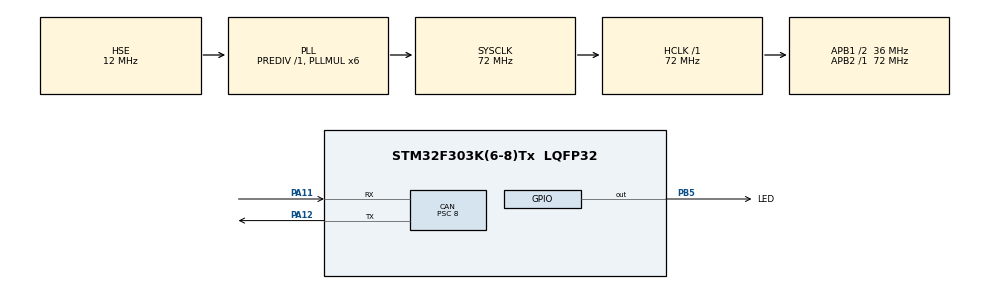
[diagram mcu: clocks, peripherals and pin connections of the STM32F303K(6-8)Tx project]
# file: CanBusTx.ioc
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CAN.BS1=CAN_BS1_7TQ
CAN.CalculateBaudRate=500000
CAN.CalculateTimeBit=1999.99
CAN.CalculateTimeQuantum=222.22222222222223
CAN.Prescaler=8
Mcu.Family=STM32F3
Mcu.Name=STM32F303K(6-8)Tx
Mcu.Package=LQFP32
NVIC.CAN_RX0_IRQn=true\:0\:0\:false\:false\:true\:true\:true
NVIC.CAN_RX1_IRQn=true\:0\:0\:false\:false\:true\:true\:true
NVIC.PriorityGroup=NVIC_PRIORITYGROUP_4
PA11.Mode=CAN_Activate
PA11.Signal=CAN_RX
PA12.Mode=CAN_Activate
PA12.Signal=CAN_TX
PA13.Mode=Serial_Wire
PA13.Signal=SYS_JTMS-SWDIO
PA14.Mode=Serial_Wire
PA14.Signal=SYS_JTCK-SWCLK
PB5.GPIO_Label=LED
PB5.Signal=GPIO_Output
PF0\ /\ OSC_IN.Mode=HSE-External-Oscillator
PF0\ /\ OSC_IN.Signal=RCC_OSC_IN
PF1\ /\ OSC_OUT.Mode=HSE-External-Oscillator
PF1\ /\ OSC_OUT.Signal=RCC_OSC_OUT
ProjectManager.HeapSize=0x200
ProjectManager.StackSize=0x400
ProjectManager.TargetToolchain=STM32CubeIDE
RCC.AHBFreq_Value=72000000
RCC.APB1CLKDivider=RCC_HCLK_DIV2
RCC.APB1Freq_Value=36000000
RCC.APB1TimFreq_Value=72000000
RCC.APB2Freq_Value=72000000
RCC.APB2TimFreq_Value=72000000
RCC.CortexFreq_Value=72000000
RCC.HCLKFreq_Value=72000000
RCC.HSE_VALUE=12000000
RCC.HSI_VALUE=8000000
RCC.PLLMUL=RCC_PLL_MUL6
RCC.PLLSourceVirtual=RCC_PLLSOURCE_HSE
RCC.SYSCLKFreq_VALUE=72000000
RCC.SYSCLKSourceVirtual=RCC_SYSCLKSOURCE_PLLCLK
board=custom

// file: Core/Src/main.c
/* USER CODE BEGIN Header */
/**
  ******************************************************************************
  * @file           : main.c
  * @brief          : Main program body
  ******************************************************************************
  * @attention
  *
  * <h2><center>&copy; Copyright (c) 2021 STMicroelectronics.
  * All rights reserved.</center></h2>
  *
  * This software component is licensed by ST under BSD 3-Clause license,
  * the "License"; You may not use this file except in compliance with the
  * License. You may obtain a copy of the License at:
  *                        opensource.org/licenses/BSD-3-Clause
  *
  ******************************************************************************
  */
/* USER CODE END Header */
#include "main.h"
#include "can.h"
#include "gpio.h"
#include <stdlib.h>

/* USER CODE BEGIN PV */
CAN_FilterTypeDef sFilterConfig;
CAN_TxHeaderTypeDef TxHeader;
CAN_RxHeaderTypeDef RxHeader;
/* USER CODE END PV */

void SystemClock_Config(void);
/* USER CODE BEGIN PFP */
void CAN1_Tx(uint8_t stdid, uint16_t TxMessage[8]);
/* USER CODE END PFP */

int main(void)
{

  /* MCU Configuration--------------------------------------------------------*/

  /* Reset of all peripherals, Initializes the Flash interface and the Systick. */
  HAL_Init();

  /* Configure the system clock */
  SystemClock_Config();

  /* Initialize all configured peripherals */
  MX_GPIO_Init();
  MX_CAN_Init();
  /* USER CODE BEGIN 2 */
  HAL_CAN_Start(&hcan);

  sFilterConfig.FilterMode = CAN_FILTERMODE_IDMASK;
  sFilterConfig.FilterScale = CAN_FILTERSCALE_32BIT;
  sFilterConfig.FilterIdHigh = 0x0000;
  sFilterConfig.FilterIdLow = 0x0000;
  sFilterConfig.FilterMaskIdHigh = 0x0000;
  sFilterConfig.FilterMaskIdLow= 0x0000;
  sFilterConfig.FilterFIFOAssignment = CAN_FILTER_FIFO0;
  sFilterConfig.FilterActivation = ENABLE;
  sFilterConfig.FilterBank = 0;

  HAL_CAN_ConfigFilter(&hcan, &sFilterConfig);
  uint8_t s=1;

  /* USER CODE END 2 */

  /* Infinite loop */
  while (1)
  {

    /* USER CODE BEGIN 3 */
	  HAL_GPIO_WritePin(LED_GPIO_Port, LED_Pin, GPIO_PIN_SET);
	  uint16_t rawdata[4];
	  uint16_t rawdata2[4];

	  rawdata[0] += s*100;
	  if (rawdata[0]<0 || rawdata[0]>8000) s*=-1;
	  rawdata[1] = rand()%6+1;				//marcia
	  rawdata[2] = rand()%3+1;				//mappa
	  rawdata[3] = rand()%2;				//drs
	  rawdata2[0] = rand()%60+50;			//oil temp
	  rawdata2[1] = rand()%20+30;			//air temp
	  rawdata2[2] = rand()%60+50;			//h2o temp
	  rawdata2[3] = rand()%4+10;			//battery voltage

	  CAN1_Tx(17,rawdata);
	  CAN1_Tx(18,rawdata2);
	  HAL_Delay(100);

  }
  /* USER CODE END 3 */
}

void SystemClock_Config(void)
{
  RCC_OscInitTypeDef RCC_OscInitStruct = {0};
  RCC_ClkInitTypeDef RCC_ClkInitStruct = {0};

  /** Initializes the RCC Oscillators according to the specified parameters
  * in the RCC_OscInitTypeDef structure.
  */
  RCC_OscInitStruct.OscillatorType = RCC_OSCILLATORTYPE_HSE;
  RCC_OscInitStruct.HSEState = RCC_HSE_ON;
  RCC_OscInitStruct.HSEPredivValue = RCC_HSE_PREDIV_DIV1;
  RCC_OscInitStruct.HSIState = RCC_HSI_ON;
  RCC_OscInitStruct.PLL.PLLState = RCC_PLL_ON;
  RCC_OscInitStruct.PLL.PLLSource = RCC_PLLSOURCE_HSE;
  RCC_OscInitStruct.PLL.PLLMUL = RCC_PLL_MUL6;
  if (HAL_RCC_OscConfig(&RCC_OscInitStruct) != HAL_OK)
  {
    Error_Handler();
  }
  /** Initializes the CPU, AHB and APB buses clocks
  */
  RCC_ClkInitStruct.ClockType = RCC_CLOCKTYPE_HCLK|RCC_CLOCKTYPE_SYSCLK
                              |RCC_CLOCKTYPE_PCLK1|RCC_CLOCKTYPE_PCLK2;
  RCC_ClkInitStruct.SYSCLKSource = RCC_SYSCLKSOURCE_PLLCLK;
  RCC_ClkInitStruct.AHBCLKDivider = RCC_SYSCLK_DIV1;
  RCC_ClkInitStruct.APB1CLKDivider = RCC_HCLK_DIV2;
  RCC_ClkInitStruct.APB2CLKDivider = RCC_HCLK_DIV1;

  if (HAL_RCC_ClockConfig(&RCC_ClkInitStruct, FLASH_LATENCY_2) != HAL_OK)
  {
    Error_Handler();

  }
}

/* USER CODE BEGIN 4 */

void CAN1_Tx(uint8_t stdid, uint16_t message[8]){

	CAN_TxHeaderTypeDef TxHeader;

	uint32_t TxMailbox;

	/*uint8_t mess[6] = {
				  //1,2,3,4,5,6
		 'H','E','L','L','O','!'
	};
	*/
	TxHeader.DLC = 8; //How many bytes do you want to send, tra 0 e 8; 0 byte oppure 8 byte, 0 è inutile
	TxHeader.StdId = stdid; // Standard Identifier, va da 0 a 0x7FF
	TxHeader.IDE = CAN_ID_STD; //Questo è sempre così, specifica che si stanno usando gli indirizzi standard
	TxHeader.RTR = CAN_RTR_DATA; //DATA O REMOTE, non so cosa sia remote

	if(HAL_CAN_AddTxMessage(&hcan, &TxHeader, message, &TxMailbox) != HAL_OK){
		Error_Handler();
	}

}

/* USER CODE END 4 */

void Error_Handler(void)
{
  __disable_irq();
  while (1)
  {
  }
}

/************************ (C) COPYRIGHT STMicroelectronics *****END OF FILE****/
